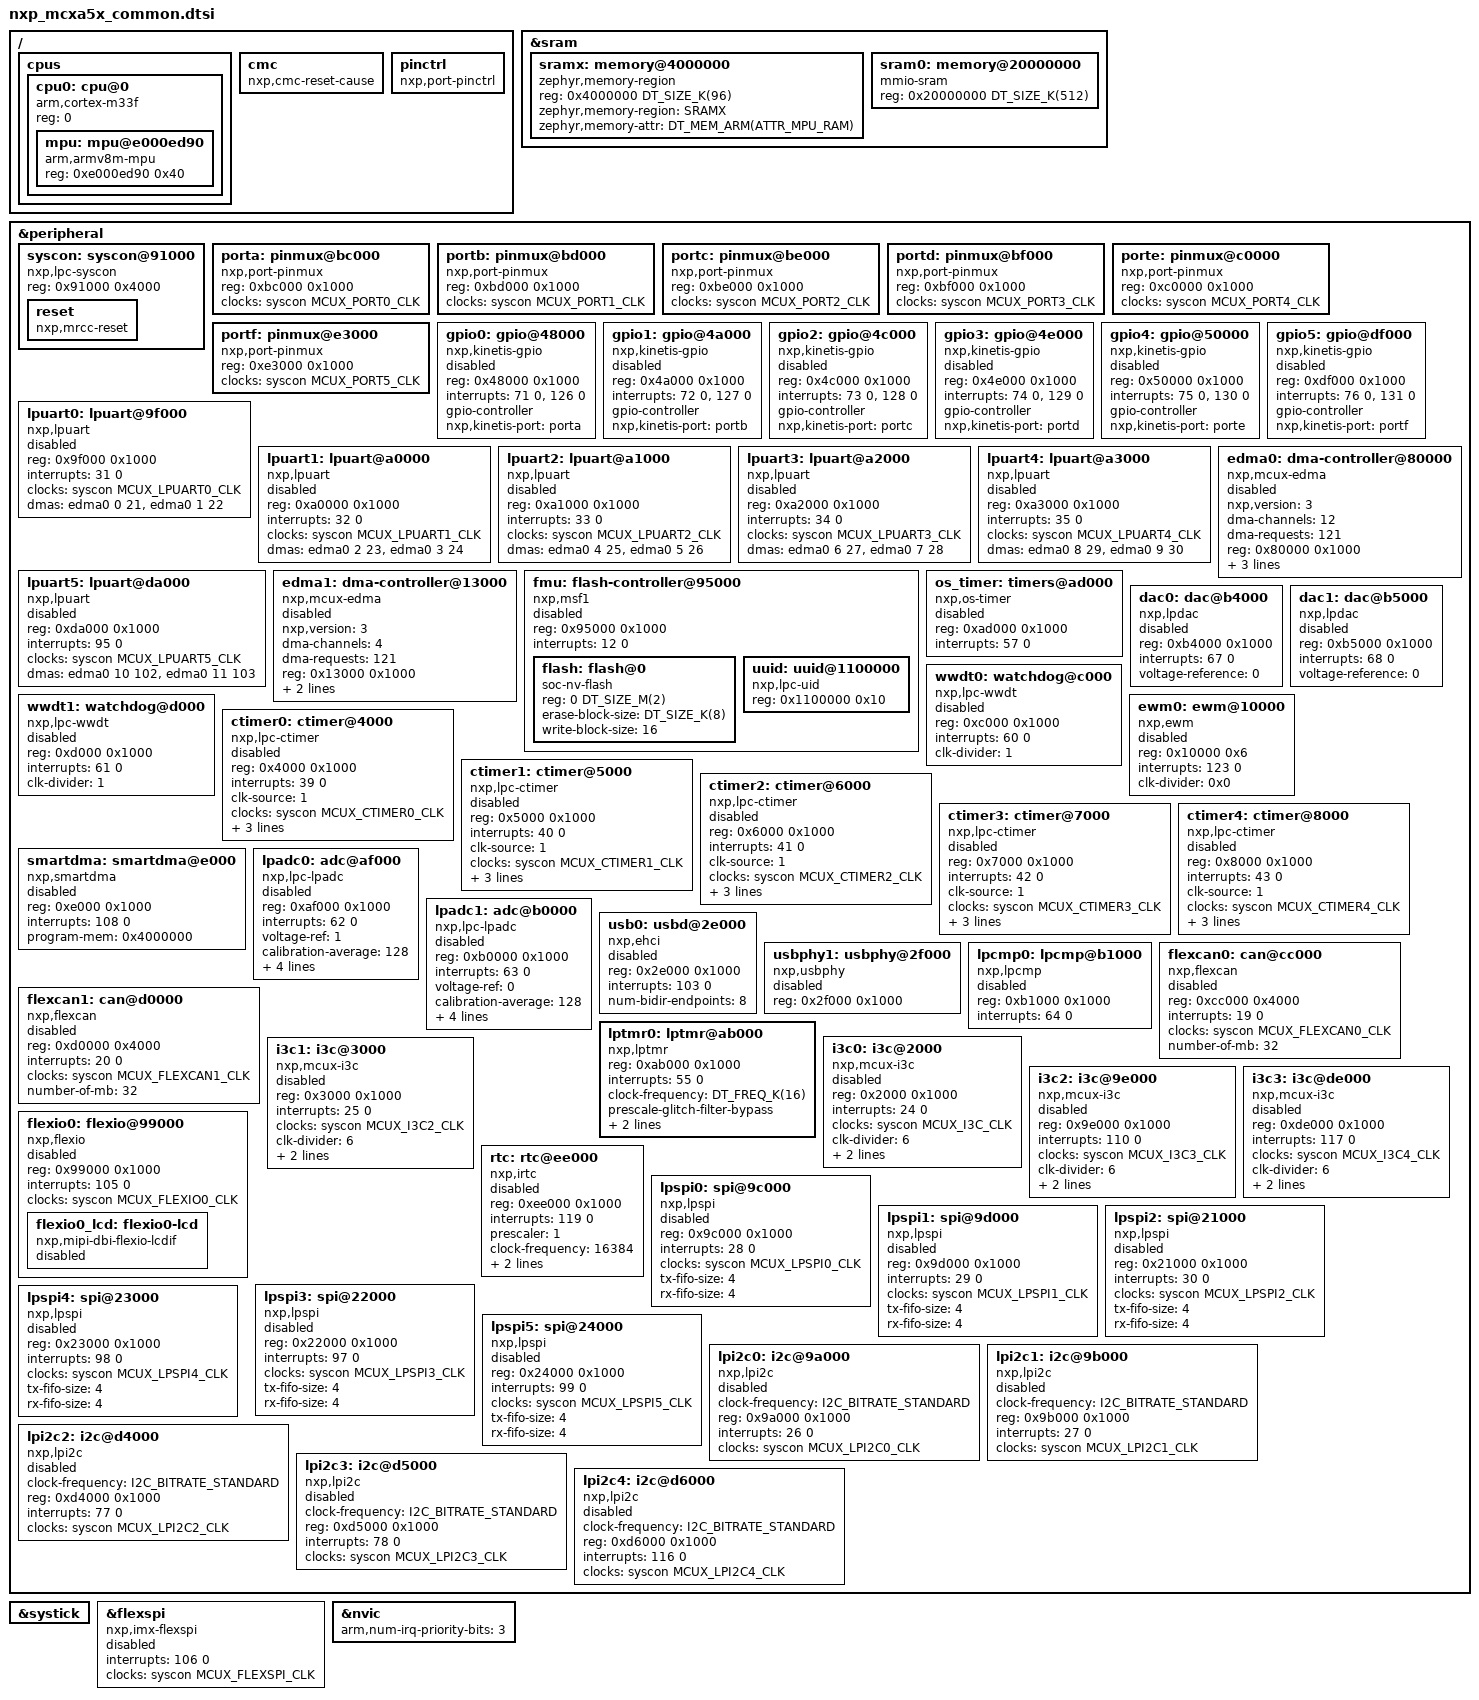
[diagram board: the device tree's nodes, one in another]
/*
 * Copyright 2025 NXP
 *
 * SPDX-License-Identifier: Apache-2.0
 */

#include <mem.h>
#include <freq.h>
#include <zephyr/dt-bindings/clock/mcux_lpc_syscon_clock.h>
#include <zephyr/dt-bindings/reset/nxp_syscon_reset_common.h>
#include <zephyr/dt-bindings/gpio/gpio.h>
#include <arm/armv8-m.dtsi>
#include <zephyr/dt-bindings/memory-attr/memory-attr-arm.h>
#include <zephyr/dt-bindings/i2c/i2c.h>

/ {
	cpus: cpus {
		#address-cells = <1>;
		#size-cells = <0>;

		cpu0: cpu@0 {
			compatible = "arm,cortex-m33f";
			reg = <0>;
			#address-cells = <1>;
			#size-cells = <1>;

			mpu: mpu@e000ed90 {
				compatible = "arm,armv8m-mpu";
				reg = <0xe000ed90 0x40>;
			};
		};
	};

	cmc {
		compatible = "nxp,cmc-reset-cause";
	};

	/* Dummy pinctrl node, filled with pin mux options at board level */
	pinctrl: pinctrl {
		compatible = "nxp,port-pinctrl";
		status = "okay";
	};
};

&sram {
	#address-cells = <1>;
	#size-cells = <1>;

	sramx: memory@4000000 {
		compatible = "zephyr,memory-region", "mmio-sram";
		reg = <0x4000000 DT_SIZE_K(96)>;
		zephyr,memory-region = "SRAMX";
		zephyr,memory-attr = <DT_MEM_ARM(ATTR_MPU_RAM)>;
	};

	/* Memory configurations:
	 *
	 * RAM 512K
	 *
	 * 8 K SRAM A0
	 * 4 K SRAM A1 and PKC SRAM 0
	 * 4 K SRAM A2 and PKC SRAM 1
	 * 16K SRAM A3
	 * 16K SRAM A4
	 * 16K SRAM A5
	 * 32K SRAM A6
	 * 32K SRAM A7
	 * 32K SRAM A8
	 * 32K SRAM A9
	 * 32K SRAM A10
	 * 32K SRAM A11
	 * 32K SRAM B0
	 * 32K SRAM B1
	 * 32K SRAM B2
	 * 32K SRAM B3
	 * 32K SRAM B4
	 * 32K SRAM B5
	 * 32K SRAM B6
	 * 32K SRAM B7
	 */
	sram0: memory@20000000 {
		compatible = "mmio-sram";
		reg = <0x20000000 DT_SIZE_K(512)>;
	};
};

&peripheral {
	#address-cells = <1>;
	#size-cells = <1>;

	syscon: syscon@91000 {
		compatible = "nxp,lpc-syscon";
		reg = <0x91000 0x4000>;
		#clock-cells = <1>;

		reset: reset {
			compatible = "nxp,mrcc-reset";
			#reset-cells = <1>;
		};
	};

	porta: pinmux@bc000 {
		compatible = "nxp,port-pinmux";
		reg = <0xbc000 0x1000>;
		clocks = <&syscon MCUX_PORT0_CLK>;
	};

	portb: pinmux@bd000 {
		compatible = "nxp,port-pinmux";
		reg = <0xbd000 0x1000>;
		clocks = <&syscon MCUX_PORT1_CLK>;
	};

	portc: pinmux@be000 {
		compatible = "nxp,port-pinmux";
		reg = <0xbe000 0x1000>;
		clocks = <&syscon MCUX_PORT2_CLK>;
	};

	portd: pinmux@bf000 {
		compatible = "nxp,port-pinmux";
		reg = <0xbf000 0x1000>;
		clocks = <&syscon MCUX_PORT3_CLK>;
	};

	porte: pinmux@c0000 {
		compatible = "nxp,port-pinmux";
		reg = <0xc0000 0x1000>;
		clocks = <&syscon MCUX_PORT4_CLK>;
	};

	portf: pinmux@e3000 {
		compatible = "nxp,port-pinmux";
		reg = <0xe3000 0x1000>;
		clocks = <&syscon MCUX_PORT5_CLK>;
	};

	gpio0: gpio@48000 {
		compatible = "nxp,kinetis-gpio";
		status = "disabled";
		reg = <0x48000 0x1000>;
		interrupts = <71 0>, <126 0>;
		gpio-controller;
		#gpio-cells = <2>;
		nxp,kinetis-port = <&porta>;
	};

	gpio1: gpio@4a000 {
		compatible = "nxp,kinetis-gpio";
		status = "disabled";
		reg = <0x4a000 0x1000>;
		interrupts = <72 0>, <127 0>;
		gpio-controller;
		#gpio-cells = <2>;
		nxp,kinetis-port = <&portb>;
	};

	gpio2: gpio@4c000 {
		compatible = "nxp,kinetis-gpio";
		status = "disabled";
		reg = <0x4c000 0x1000>;
		interrupts = <73 0>, <128 0>;
		gpio-controller;
		#gpio-cells = <2>;
		nxp,kinetis-port = <&portc>;
	};

	gpio3: gpio@4e000 {
		compatible = "nxp,kinetis-gpio";
		status = "disabled";
		reg = <0x4e000 0x1000>;
		interrupts = <74 0>, <129 0>;
		gpio-controller;
		#gpio-cells = <2>;
		nxp,kinetis-port = <&portd>;
	};

	gpio4: gpio@50000 {
		compatible = "nxp,kinetis-gpio";
		status = "disabled";
		reg = <0x50000 0x1000>;
		interrupts = <75 0>, <130 0>;
		gpio-controller;
		#gpio-cells = <2>;
		nxp,kinetis-port = <&porte>;
	};

	gpio5: gpio@df000 {
		compatible = "nxp,kinetis-gpio";
		status = "disabled";
		reg = <0xdf000 0x1000>;
		interrupts = <76 0>, <131 0>;
		gpio-controller;
		#gpio-cells = <2>;
		nxp,kinetis-port = <&portf>;
	};

	lpuart0: lpuart@9f000 {
		compatible = "nxp,lpuart";
		status = "disabled";
		reg = <0x9f000 0x1000>;
		interrupts = <31 0>;
		clocks = <&syscon MCUX_LPUART0_CLK>;
		/* DMA channels 0 and 1, muxed to LPUART RX and TX */
		dmas = <&edma0 0 21>, <&edma0 1 22>;
		dma-names = "rx", "tx";
	};

	lpuart1: lpuart@a0000 {
		compatible = "nxp,lpuart";
		status = "disabled";
		reg = <0xa0000 0x1000>;
		interrupts = <32 0>;
		clocks = <&syscon MCUX_LPUART1_CLK>;
		/* DMA channels 2 and 3, muxed to LPUART RX and TX */
		dmas = <&edma0 2 23>, <&edma0 3 24>;
		dma-names = "rx", "tx";
	};

	lpuart2: lpuart@a1000 {
		compatible = "nxp,lpuart";
		status = "disabled";
		reg = <0xa1000 0x1000>;
		interrupts = <33 0>;
		clocks = <&syscon MCUX_LPUART2_CLK>;
		/* DMA channels 4 and 5, muxed to LPUART RX and TX */
		dmas = <&edma0 4 25>, <&edma0 5 26>;
		dma-names = "rx", "tx";
	};

	lpuart3: lpuart@a2000 {
		compatible = "nxp,lpuart";
		status = "disabled";
		reg = <0xa2000 0x1000>;
		interrupts = <34 0>;
		clocks = <&syscon MCUX_LPUART3_CLK>;
		/* DMA channels 6 and 7, muxed to LPUART RX and TX */
		dmas = <&edma0 6 27>, <&edma0 7 28>;
		dma-names = "rx", "tx";
	};

	lpuart4: lpuart@a3000 {
		compatible = "nxp,lpuart";
		status = "disabled";
		reg = <0xa3000 0x1000>;
		interrupts = <35 0>;
		clocks = <&syscon MCUX_LPUART4_CLK>;
		/* DMA channels 8 and 9, muxed to LPUART RX and TX */
		dmas = <&edma0 8 29>, <&edma0 9 30>;
		dma-names = "rx", "tx";
	};

	lpuart5: lpuart@da000 {
		compatible = "nxp,lpuart";
		status = "disabled";
		reg = <0xda000 0x1000>;
		interrupts = <95 0>;
		clocks = <&syscon MCUX_LPUART5_CLK>;
		/* DMA channels 10 and 11, muxed to LPUART RX and TX */
		dmas = <&edma0 10 102>, <&edma0 11 103>;
		dma-names = "rx", "tx";
	};

	edma0: dma-controller@80000 {
		#dma-cells = <2>;
		compatible = "nxp,mcux-edma";
		nxp,version = <3>;
		dma-channels = <12>;
		dma-requests = <121>;

		reg = <0x80000 0x1000>;
		interrupts = <2 0>, <3 0>, <4 0>,
			     <5 0>, <6 0>, <7 0>, <8 0>,
			     <9 0>, <134 0>, <135 0>, <136 0>,
			     <137 0>;
		no-error-irq;
		status = "disabled";
	};

	edma1: dma-controller@13000 {
		#dma-cells = <2>;
		compatible = "nxp,mcux-edma";
		nxp,version = <3>;
		dma-channels = <4>;
		dma-requests = <121>;

		reg = <0x13000 0x1000>;
		interrupts = <142 0>, <143 0>, <144 0>, <145 0>;
		no-error-irq;
		status = "disabled";
	};

	fmu: flash-controller@95000 {
		compatible = "nxp,msf1";
		reg = <0x95000 0x1000>;
		interrupts = <12 0>;
		status = "disabled";

		#address-cells = <1>;
		#size-cells = <1>;

		flash: flash@0 {
			compatible = "soc-nv-flash";
			reg = <0 DT_SIZE_M(2)>;
			erase-block-size = <DT_SIZE_K(8)>;
			write-block-size = <16>;
		};

		uuid: uuid@1100000 {
			compatible = "nxp,lpc-uid";
			reg = <0x1100000 0x10>;
		};
	};

	os_timer: timers@ad000 {
		compatible = "nxp,os-timer";
		reg = <0xad000 0x1000>;
		interrupts = <57 0>;
		status = "disabled";
	};

	dac0: dac@b4000 {
		compatible = "nxp,lpdac";
		reg = <0xb4000 0x1000>;
		interrupts = <67 0>;
		status = "disabled";
		voltage-reference = <0>;
		#io-channel-cells = <1>;
	};

	dac1: dac@b5000 {
		compatible = "nxp,lpdac";
		reg = <0xb5000 0x1000>;
		interrupts = <68 0>;
		status = "disabled";
		voltage-reference = <0>;
		#io-channel-cells = <1>;
	};

	wwdt0: watchdog@c000 {
		compatible = "nxp,lpc-wwdt";
		reg = <0xc000 0x1000>;
		interrupts = <60 0>;
		status = "disabled";
		clk-divider = <1>;
	};

	wwdt1: watchdog@d000 {
		compatible = "nxp,lpc-wwdt";
		reg = <0xd000 0x1000>;
		interrupts = <61 0>;
		status = "disabled";
		clk-divider = <1>;
	};

	ewm0: ewm@10000 {
		compatible = "nxp,ewm";
		reg = <0x10000 0x6>;
		interrupts = <123 0>;
		status = "disabled";
		clk-divider = <0x0>;
	};

	ctimer0: ctimer@4000 {
		compatible = "nxp,lpc-ctimer";
		reg = <0x4000 0x1000>;
		interrupts = <39 0>;
		status = "disabled";
		clk-source = <1>;
		clocks = <&syscon MCUX_CTIMER0_CLK>;
		mode = <0>;
		input = <0>;
		prescale = <0>;
	};

	ctimer1: ctimer@5000 {
		compatible = "nxp,lpc-ctimer";
		reg = <0x5000 0x1000>;
		interrupts = <40 0>;
		status = "disabled";
		clk-source = <1>;
		clocks = <&syscon MCUX_CTIMER1_CLK>;
		mode = <0>;
		input = <0>;
		prescale = <0>;
	};

	ctimer2: ctimer@6000 {
		compatible = "nxp,lpc-ctimer";
		reg = <0x6000 0x1000>;
		interrupts = <41 0>;
		status = "disabled";
		clk-source = <1>;
		clocks = <&syscon MCUX_CTIMER2_CLK>;
		mode = <0>;
		input = <0>;
		prescale = <0>;
	};

	ctimer3: ctimer@7000 {
		compatible = "nxp,lpc-ctimer";
		reg = <0x7000 0x1000>;
		interrupts = <42 0>;
		status = "disabled";
		clk-source = <1>;
		clocks = <&syscon MCUX_CTIMER3_CLK>;
		mode = <0>;
		input = <0>;
		prescale = <0>;
	};

	ctimer4: ctimer@8000 {
		compatible = "nxp,lpc-ctimer";
		reg = <0x8000 0x1000>;
		interrupts = <43 0>;
		status = "disabled";
		clk-source = <1>;
		clocks = <&syscon MCUX_CTIMER4_CLK>;
		mode = <0>;
		input = <0>;
		prescale = <0>;
	};

	smartdma: smartdma@e000 {
		compatible = "nxp,smartdma";
		reg = <0xe000 0x1000>;
		status = "disabled";
		interrupts = <108 0>;
		program-mem = <0x4000000>;
		#dma-cells = <0>;
	};

	lpadc0: adc@af000 {
		compatible = "nxp,lpc-lpadc";
		reg = <0xaf000 0x1000>;
		interrupts = <62 0>;
		status = "disabled";
		voltage-ref = <1>;
		calibration-average = <128>;
		power-level = <0>;
		offset-value-a = <0>;
		offset-value-b = <0>;
		#io-channel-cells = <1>;
		clocks = <&syscon MCUX_LPADC1_CLK>;
	};

	lpadc1: adc@b0000 {
		compatible = "nxp,lpc-lpadc";
		reg = <0xb0000 0x1000>;
		interrupts = <63 0>;
		status = "disabled";
		voltage-ref = <0>;
		calibration-average = <128>;
		power-level = <1>;
		offset-value-a = <0>;
		offset-value-b = <0>;
		#io-channel-cells = <1>;
		clocks = <&syscon MCUX_LPADC2_CLK>;
	};

	usb0: usbd@2e000 {
		compatible = "nxp,ehci";
		reg = <0x2e000 0x1000>;
		interrupts = <103 0>;
		interrupt-names = "usb_otg";
		num-bidir-endpoints = <8>;
		status = "disabled";
	};

	usbphy1: usbphy@2f000 {
		compatible = "nxp,usbphy";
		reg = <0x2f000 0x1000>;
		status = "disabled";
	};

	lpcmp0: lpcmp@b1000 {
		compatible = "nxp,lpcmp";
		reg = <0xb1000 0x1000>;
		interrupts = <64 0>;
		status = "disabled";
		#io-channel-cells = <2>;
	};

	flexcan0: can@cc000 {
		compatible = "nxp,flexcan";
		reg = <0xcc000 0x4000>;
		interrupts = <19 0>;
		interrupt-names = "common";
		clocks = <&syscon MCUX_FLEXCAN0_CLK>;
		number-of-mb = <32>;
		status = "disabled";
	};

	flexcan1: can@d0000 {
		compatible = "nxp,flexcan";
		reg = <0xd0000 0x4000>;
		interrupts = <20 0>;
		interrupt-names = "common";
		clocks = <&syscon MCUX_FLEXCAN1_CLK>;
		number-of-mb = <32>;
		status = "disabled";
	};

	lptmr0: lptmr@ab000 {
		compatible = "nxp,lptmr";
		reg = <0xab000 0x1000>;
		interrupts = <55 0>;
		clock-frequency = <DT_FREQ_K(16)>;
		prescale-glitch-filter-bypass;
		clk-source = <1>;
		resolution = <32>;
	};

	i3c0: i3c@2000 {
		compatible = "nxp,mcux-i3c";
		reg = <0x2000 0x1000>;
		interrupts = <24 0>;
		clocks = <&syscon MCUX_I3C_CLK>;
		clk-divider = <6>;
		clk-divider-slow = <1>;
		clk-divider-tc = <1>;
		status = "disabled";
		#address-cells = <3>;
		#size-cells = <0>;
	};

	i3c1: i3c@3000 {
		compatible = "nxp,mcux-i3c";
		reg = <0x3000 0x1000>;
		interrupts = <25 0>;
		clocks = <&syscon MCUX_I3C2_CLK>;
		clk-divider = <6>;
		clk-divider-slow = <1>;
		clk-divider-tc = <1>;
		status = "disabled";
		#address-cells = <3>;
		#size-cells = <0>;
	};

	i3c2: i3c@9e000 {
		compatible = "nxp,mcux-i3c";
		reg = <0x9e000 0x1000>;
		interrupts = <110 0>;
		clocks = <&syscon MCUX_I3C3_CLK>;
		clk-divider = <6>;
		clk-divider-slow = <1>;
		clk-divider-tc = <1>;
		status = "disabled";
		#address-cells = <3>;
		#size-cells = <0>;
	};

	i3c3: i3c@de000 {
		compatible = "nxp,mcux-i3c";
		reg = <0xde000 0x1000>;
		interrupts = <117 0>;
		clocks = <&syscon MCUX_I3C4_CLK>;
		clk-divider = <6>;
		clk-divider-slow = <1>;
		clk-divider-tc = <1>;
		status = "disabled";
		#address-cells = <3>;
		#size-cells = <0>;
	};

	flexio0: flexio@99000 {
		compatible = "nxp,flexio";
		reg = <0x99000 0x1000>;
		status = "disabled";
		interrupts = <105 0>;
		clocks = <&syscon MCUX_FLEXIO0_CLK>;

		flexio0_lcd: flexio0-lcd {
			compatible = "nxp,mipi-dbi-flexio-lcdif";
			status = "disabled";
		};
	};

	rtc: rtc@ee000 {
		compatible = "nxp,irtc";
		reg = <0xee000 0x1000>;
		status = "disabled";
		interrupts = <119 0>;
		prescaler = <1>;
		clock-frequency = <16384>;
		clock-src = <0>;
		alarms-count = <1>;
	};

	lpspi0: spi@9c000 {
		compatible = "nxp,lpspi";
		reg = <0x9c000 0x1000>;
		interrupts = <28 0>;
		clocks = <&syscon MCUX_LPSPI0_CLK>;
		tx-fifo-size = <4>;
		rx-fifo-size = <4>;
		#address-cells = <1>;
		#size-cells = <0>;
		status = "disabled";
	};

	lpspi1: spi@9d000 {
		compatible = "nxp,lpspi";
		reg = <0x9d000 0x1000>;
		interrupts = <29 0>;
		clocks = <&syscon MCUX_LPSPI1_CLK>;
		tx-fifo-size = <4>;
		rx-fifo-size = <4>;
		#address-cells = <1>;
		#size-cells = <0>;
		status = "disabled";
	};

	lpspi2: spi@21000 {
		compatible = "nxp,lpspi";
		reg = <0x21000 0x1000>;
		interrupts = <30 0>;
		clocks = <&syscon MCUX_LPSPI2_CLK>;
		tx-fifo-size = <4>;
		rx-fifo-size = <4>;
		#address-cells = <1>;
		#size-cells = <0>;
		status = "disabled";
	};

	lpspi3: spi@22000 {
		compatible = "nxp,lpspi";
		reg = <0x22000 0x1000>;
		interrupts = <97 0>;
		clocks = <&syscon MCUX_LPSPI3_CLK>;
		tx-fifo-size = <4>;
		rx-fifo-size = <4>;
		#address-cells = <1>;
		#size-cells = <0>;
		status = "disabled";
	};

	lpspi4: spi@23000 {
		compatible = "nxp,lpspi";
		reg = <0x23000 0x1000>;
		interrupts = <98 0>;
		clocks = <&syscon MCUX_LPSPI4_CLK>;
		tx-fifo-size = <4>;
		rx-fifo-size = <4>;
		#address-cells = <1>;
		#size-cells = <0>;
		status = "disabled";
	};

	lpspi5: spi@24000 {
		compatible = "nxp,lpspi";
		reg = <0x24000 0x1000>;
		interrupts = <99 0>;
		clocks = <&syscon MCUX_LPSPI5_CLK>;
		tx-fifo-size = <4>;
		rx-fifo-size = <4>;
		#address-cells = <1>;
		#size-cells = <0>;
		status = "disabled";
	};

	lpi2c0: i2c@9a000 {
		compatible = "nxp,lpi2c";
		clock-frequency = <I2C_BITRATE_STANDARD>;
		#address-cells = <1>;
		#size-cells = <0>;
		reg = <0x9a000 0x1000>;
		interrupts = <26 0>;
		clocks = <&syscon MCUX_LPI2C0_CLK>;
		status = "disabled";
	};

	lpi2c1: i2c@9b000 {
		compatible = "nxp,lpi2c";
		clock-frequency = <I2C_BITRATE_STANDARD>;
		#address-cells = <1>;
		#size-cells = <0>;
		reg = <0x9b000 0x1000>;
		interrupts = <27 0>;
		clocks = <&syscon MCUX_LPI2C1_CLK>;
		status = "disabled";
	};

	lpi2c2: i2c@d4000 {
		compatible = "nxp,lpi2c";
		clock-frequency = <I2C_BITRATE_STANDARD>;
		#address-cells = <1>;
		#size-cells = <0>;
		reg = <0xd4000 0x1000>;
		interrupts = <77 0>;
		clocks = <&syscon MCUX_LPI2C2_CLK>;
		status = "disabled";
	};

	lpi2c3: i2c@d5000 {
		compatible = "nxp,lpi2c";
		clock-frequency = <I2C_BITRATE_STANDARD>;
		#address-cells = <1>;
		#size-cells = <0>;
		reg = <0xd5000 0x1000>;
		interrupts = <78 0>;
		clocks = <&syscon MCUX_LPI2C3_CLK>;
		status = "disabled";
	};

	lpi2c4: i2c@d6000 {
		compatible = "nxp,lpi2c";
		clock-frequency = <I2C_BITRATE_STANDARD>;
		#address-cells = <1>;
		#size-cells = <0>;
		reg = <0xd6000 0x1000>;
		interrupts = <116 0>;
		clocks = <&syscon MCUX_LPI2C4_CLK>;
		status = "disabled";
	};
};

&systick {
	status = "okay";
};

&flexspi {
	compatible = "nxp,imx-flexspi";
	interrupts = <106 0>;
	#address-cells = <1>;
	#size-cells = <0>;
	status = "disabled";
	clocks = <&syscon MCUX_FLEXSPI_CLK>;
};

&nvic {
	arm,num-irq-priority-bits = <3>;
};
